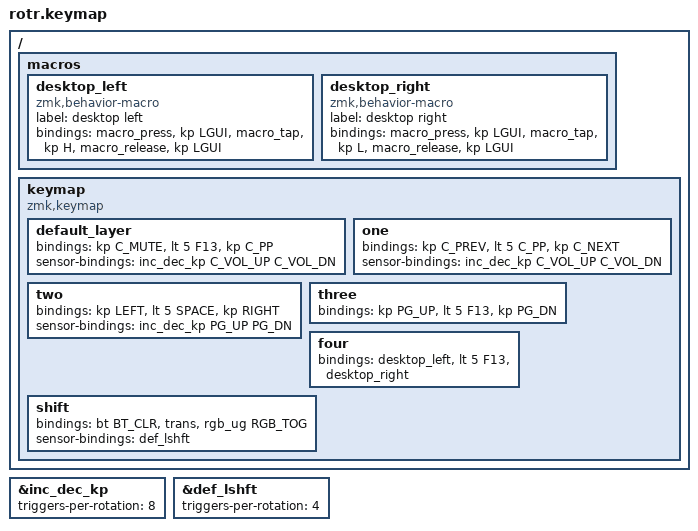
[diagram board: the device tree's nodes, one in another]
#include <behaviors.dtsi>
#include <dt-bindings/zmk/keys.h>
#include <dt-bindings/zmk/rgb.h>
#include <dt-bindings/zmk/bt.h>

&inc_dec_kp {
	triggers-per-rotation = <8>;
};
&def_lshft {
	triggers-per-rotation = <4>;
};

/ {
    macros {
        desktop_left: desktop_left {
            label = "desktop left";
            compatible = "zmk,behavior-macro";
            #binding-cells = <0>;
            bindings
                = <&macro_press &kp LGUI>
                , <&macro_tap &kp H>
                , <&macro_release &kp LGUI>
                ;
        };
        desktop_right: desktop_right {
            label = "desktop right";
            compatible = "zmk,behavior-macro";
            #binding-cells = <0>;
            bindings
                = <&macro_press &kp LGUI>
                , <&macro_tap &kp L>
                , <&macro_release &kp LGUI>
                ;
        };
    };
};

/ {
	keymap {
		compatible = "zmk,keymap";

		default_layer {
			//PREV | PLAY/PAUSE | NEXT
			bindings = <&kp C_MUTE &lt 5 F13 &kp C_PP>;
			sensor-bindings = <&inc_dec_kp C_VOL_UP C_VOL_DN>;
		};
		one {
			//PREV | PLAY/PAUSE | NEXT
			bindings = <&kp C_PREV &lt 5 C_PP &kp C_NEXT>;
			sensor-bindings = <&inc_dec_kp C_VOL_UP C_VOL_DN>;
		};
		two {
			//PREV | PLAY/PAUSE | NEXT
			bindings = <&kp LEFT &lt 5 SPACE &kp RIGHT>;
			sensor-bindings = <&inc_dec_kp PG_UP PG_DN>;
		};
		three {
			//PREV | PLAY/PAUSE | NEXT
			bindings = <&kp PG_UP &lt 5 F13 &kp PG_DN>;
		};
		four {
			//PREV | PLAY/PAUSE | NEXT
			bindings = <&desktop_left &lt 5 F13 &desktop_right>;
		};
		shift {
			//PREV | PLAY/PAUSE | NEXT
			bindings = <&bt BT_CLR &trans &rgb_ug RGB_TOG>;
			sensor-bindings = <&def_lshft>;
		};
	};
};
